# CPU_CTI register map
Vendor: Texas Instruments
Peripheral module from a debugger description file (folder CC26x4).
Registers are 32-bit, access per field, reset 0x0 unless marked. A register's access mark holds for its fields unless they carry their own. Offsets are as the file gives them; lines under a group give offsets from that group; [hi:lo] are bit positions; {n}, {i} and the like mark numbered series; 'fields as' and 'values as' point back to an identical list; <NAME> marks a mode.

## CPU_CTI
0x00 CTICONTROL
  [0] GLBEN rw — Enables or disables the CTI.
0x10 CTIINTACK — CTI Interrupt Acknowledge Register
  [7:0] INTACK wo — Acknowledges the corresponding ctitrigout output. There is one bit of the register for each ctitrigout output. When a 1 is written to a bit in this register, the corresponding ctitrigout is acknowledged, causing it to be cleared
0x14 CTIAPPSET — CTI Application Trigger Set Register
  [3:0] APPSET rw — Setting a bit HIGH generates a channel event for the selected channel. There is one bit of the register for each channel. Reads as follows: 0 Application trigger is inactive. 1 Application trigger is active. Writes as follows: 0 No effect. 1 Generate channel event.
0x18 CTIAPPCLEAR — CTI Application Trigger Clear Register
  [3:0] APPCLEAR rw — Sets the corresponding bits in the CTIAPPSET to 0. There is one bit of the register for each channel.On writes, for each bit: 0 Has no effect. 1 Clears the corresponding channel event.Setting a bit HIGH generates a channel event for the selected channel. There is one bit of the register for each channel. Reads as follows: 0 Application trigger is inactive. 1 Application trigger is active. Writes as follows: 0 No effect. 1 Generate channel event.
0x1C CTIAPPPULSE — CTI Application Pulse Register
  [3:0] APPULSE wo — Setting a bit HIGH generates a channel event pulse for the selected channel. There is one bit of the register for each channel. On writes, for each bit: 0 Has no effect. 1 Generate an event pulse on the corresponding channel.
{0x20+4i} CTIINEN{i} (i=0..7) — CTI Trigger to Channel Enable Registers
  [3:0] TRIGINEN rw — Enables a cross trigger event to the corresponding channel when a ctitrigin input is activated. There is one bit of the field for each of the four channels. On writes, for each bit: 0 Input trigger {i} events are ignored by the corresponding channel. 1 When an event is received on input trigger {i}, ctitrigin[{i}], generate an event on the channel corresponding to this bit.
{0xA0+4i} CTIOUTEN{i} (i=0..7) — CTI Trigger to Channel Enable Registers
  [3:0] TRIGOUTEN rw — Enables a cross trigger event to ctitrigout when the corresponding channel is activated. There is one bit of the field for each of the four channels. On writes, for each bit 0 The corresponding channel is ignored by the output trigger {i}. 1 When an event occurs on the channel corresponding to this bit, generate an event on output event {i}, ctitrigout[{i}].
0x130 CTITRIGINSTATUS ro — CTI Trigger to Channel Enable Registers
  [7:0] TRIGINSTATUS — Shows the status of the ctitrigin inputs. There is one bit of the field for each trigger input.Because the register provides a view of the raw ctitrigin inputs, the reset value is UNKNOWN. 1 ctitrigin is active. 0 ctitrigin is inactive
0x134 CTITRIGOUTSTATUS ro — CTI Trigger In Status Register
  [7:0] TRIGOUTSTATUS — Shows the status of the ctitrigout outputs. There is one bit of the field for each trigger output. 1 ctitrigout is active. 0 ctitrigout is inactive.
0x138 CTICHINSTATUS ro — CTI Channel In Status Register
  [3:0] CTICHINSTATUS — Shows the status of the ctichin inputs. There is one bit of the field for each channel input.Because the register provides a view of the raw ctichin inputs, the reset value is UNKNOWN. 0 ctichin is inactive. 1 ctichin is active.
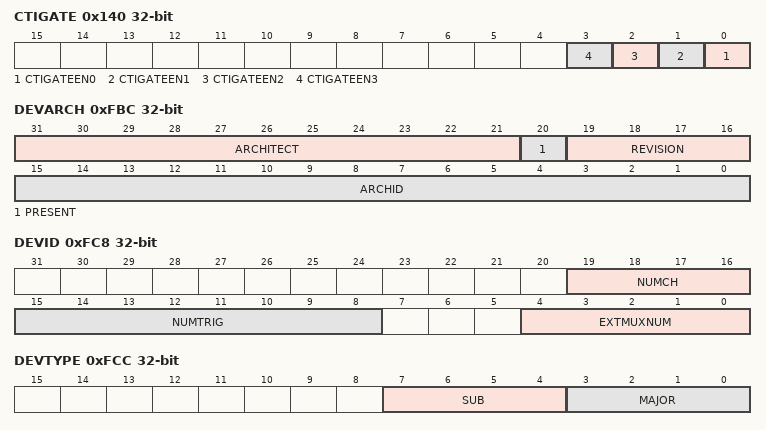
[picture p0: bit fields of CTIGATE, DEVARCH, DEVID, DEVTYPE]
0x140 CTIGATE — Enable CTI Channel Gate register
  [n] CTIGATEEN{n} rw (n=0..3) — Enable ctichout{n}. Set to 0 to disable channel propagation.
0x144 ASICCTL — External Multiplexer Control register
  [7:0] ASICCTL rw — When external multiplexing is implemented for trigger signals, then the number of multiplexed signals on each trigger must be shown in the Device ID Register. This is done using a Verilog define EXTMUXNUM
0xEE4 ITCHOUT — Integration Test Channel Output register
  [3:0] CTCHOUT wo — Sets the value of the ctichout outputs
0xEE8 ITTRIGOUT — Integration Test Trigger Output register
  [7:0] CTTRIGOUT wo — Sets the value of the ctitrigout outputs
0xEF4 ITCHIN ro — Integration Test Channel Input register
  [3:0] CTCHIN — Reads the value of the ctichin inputs
0xF00 ITCTRL — Integration Mode Control register
  [0] IME rw — Integration Mode Enable. 0 Disable integration mode. 1 Enable integration mode
0xFBC DEVARCH ro — Device Architecture register
  [31:21] ARCHITECT — Indicates the component architect: 0x23B ARM
  [20] PRESENT — Indicates whether the DEVARCH register is present: 0x1 Present.
  [19:16] REVISION — Indicates the architecture revision: 0x1 Revision 0.
  [15:0] ARCHID — Indicates the component: 0x0A34 CoreSight GPR
0xFC8 DEVID ro — Device Configuration register
  [19:16] NUMCH — Number of ECT channels available
  [15:8] NUMTRIG — Number of ECT triggers available
  [4:0] EXTMUXNUM — Indicates the number of multiplexers available on Trigger Inputs and Trigger Outputs that are using asicctl. The default value of 0b00000 indicates that no multiplexing is present. This value of this bit depends on the Verilog define EXTMUXNUM that you must change accordingly.
0xFCC DEVTYPE ro — Device Type Identifier register
  [7:4] SUB — Sub-classification of the type of the debug component as specified in the ARM Architecture Specification within the major classification as specified in the MAJOR field. 0b0001 Indicates that this component is a cross-triggering component
  [3:0] MAJOR — Major classification of the type of the debug component as specified in the ARM Architecture Specification for this debug and trace component. 0b0100 Indicates that this component allows a debugger to control other components in a CoreSight SoC-400 system.
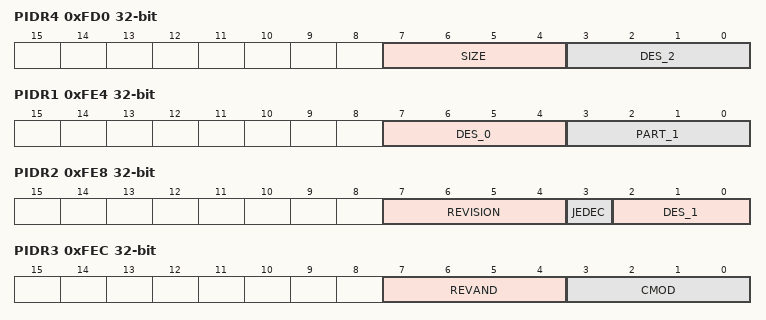
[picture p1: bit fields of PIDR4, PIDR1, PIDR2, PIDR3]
0xFD0 PIDR4 ro — CoreSight Periperal ID4
  [7:4] SIZE — Always 0b0000. Indicates that the device only occupies 4KB of memory.
  [3:0] DES_2 — Together, PIDR1.DES_0, PIDR2.DES_1, and PIDR4.DES_2 identify the designer of the component. 0b0100 JEDEC continuation code.
{0xFC0+4i} PIDR{i} ro (i=5..7) — CoreSight Periperal ID{i}
0xFE0 PIDR0 ro — CoreSight Periperal ID0
  [7:0] PART_0 — Bits[7:0] of the 12-bit part number of the component. The designer of the component assigns this part number. 0x06 Indicates bits[7:0] of the part number of the component.
0xFE4 PIDR1 ro — CoreSight Periperal ID1
  [7:4] DES_0 — Together, PIDR1.DES_0, PIDR2.DES_1, and PIDR4.DES_2 identify the designer of the component. 0b1011 ARM. Bits[3:0] of the JEDEC JEP106 Identity Code.
  [3:0] PART_1 — Bits[11:8] of the 12-bit part number of the component. The designer of the component assigns this part number. 0b1001 Indicates bits[11:8] of the part number of the component.
0xFE8 PIDR2 ro — CoreSight Periperal ID2
  [7:4] REVISION — 0b0101 This device is at r1p0.
  [3] JEDEC — Always 1. Indicates that the JEDEC-assigned designer ID is used
  [2:0] DES_1 — Together, PIDR1.DES_0, PIDR2.DES_1, and PIDR4.DES_2 identify the designer of the component. 0b011 ARM. Bits[6:4] of the JEDEC JEP106 Identity Code
0xFEC PIDR3 ro — CoreSight Periperal ID3
  [7:4] REVAND — Indicates minor errata fixes specific to the revision of the component being used, for example metal fixes after implementation. In most cases, this field is 0b0000. ARM recommends that the component designers ensure that a metal fix can change this field if required, for example, by driving it from registers that reset to 0b0000. 0b0000 Indicates that there are no errata fixes to this component.
  [3:0] CMOD — Customer Modified. Indicates whether the customer has modified the behavior of the component. In most cases, this field is 0b0000. Customers change this value when they make authorized modifications to this component. 0b0000 Indicates that the customer has not modified this component.
0xFF0 CIDR0 ro — CoreSight Component ID0
  [7:0] PRMBL_0 — Preamble[0]. Contains bits[7:0] of the component identification code. 0x0D Bits[7:0] of the identification code.
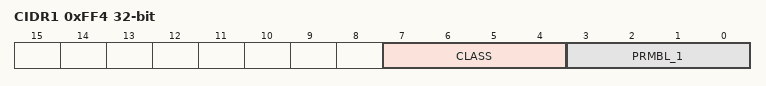
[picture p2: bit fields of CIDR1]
0xFF4 CIDR1 ro — CoreSight Component ID1
  [7:4] CLASS — Class of the component, for example, whether the component is a ROM table or a generic CoreSight component. Contains bits[15:12] of the component identification code. 0b1001 Indicates that the component is a CoreSight component.
  [3:0] PRMBL_1 — Preamble[1]. Contains bits[11:8] of the component identification code. 0b0000 Bits[11:8] of the identification code.
0xFF8 CIDR2 ro — CoreSight Component ID2
  [7:0] PRMBL_2 — Preamble[2]. Contains bits[23:16] of the component identification code. 0x05 Bits[23:16] of the identification code.
0xFFC CIDR3 ro — CoreSight Component ID3
  [7:0] PRMBL_3 — Preamble[3]. Contains bits[31:24] of the component identification code. 0xB1 Bits[31:24] of the identification code.
